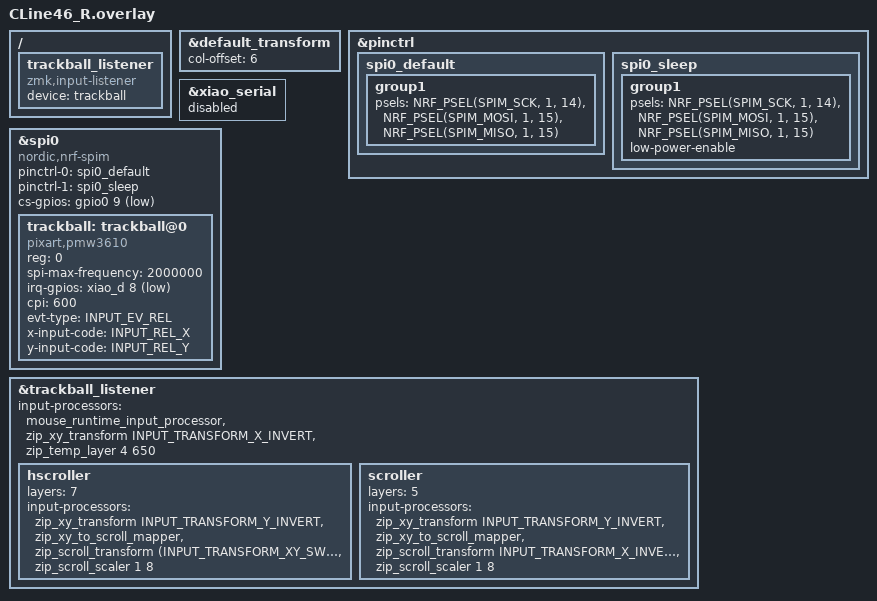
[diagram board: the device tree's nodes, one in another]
#include "CLine46.dtsi"
#include <zephyr/dt-bindings/input/input-event-codes.h>
#include <input/processors.dtsi>
#include <input/processors/runtime-input-processor.dtsi>
#include <behaviors/battery_history_request.dtsi>

&default_transform {
    col-offset = <6>;
};


/ {
    trackball_listener {
        status = "okay";
        compatible = "zmk,input-listener";
        device = <&trackball>;
    };
};

&pinctrl {
    spi0_default: spi0_default {
        group1 {
            psels = <NRF_PSEL(SPIM_SCK, 1, 14)>,
                <NRF_PSEL(SPIM_MOSI, 1, 15)>,
                <NRF_PSEL(SPIM_MISO, 1, 15)>;
        };
    };

    spi0_sleep: spi0_sleep {
        group1 {
            psels = <NRF_PSEL(SPIM_SCK, 1, 14)>,
                <NRF_PSEL(SPIM_MOSI, 1, 15)>,
                <NRF_PSEL(SPIM_MISO, 1, 15)>;
            low-power-enable;
        };
    };
};


&xiao_serial { status = "disabled"; };

&spi0 {
    status = "okay";
    compatible = "nordic,nrf-spim";
    pinctrl-0 = <&spi0_default>;
    pinctrl-1 = <&spi0_sleep>;
    pinctrl-names = "default", "sleep";
    cs-gpios = <&gpio0 9 GPIO_ACTIVE_LOW>;  //P0.09を指定(CS)

    trackball: trackball@0 {
        status = "okay";
        compatible = "pixart,pmw3610";
        reg = <0>;
        spi-max-frequency = <2000000>;
        irq-gpios = <&xiao_d 8 (GPIO_ACTIVE_LOW | GPIO_PULL_UP)>;
        cpi = <600>;
        //swap-xy;
        evt-type = <INPUT_EV_REL>;
        x-input-code = <INPUT_REL_X>;
        y-input-code = <INPUT_REL_Y>;
    };
};

// Overrides for the input listener node
&trackball_listener {
    status = "okay";
    input-processors =<&mouse_runtime_input_processor>,
        //<&zip_xy_transform INPUT_TRANSFORM_Y_INVERT>,         //Y軸反転
        //<&zip_xy_transform INPUT_TRANSFORM_XY_SWAP>,        //X軸とY軸の入れ替え
        <&zip_xy_transform INPUT_TRANSFORM_X_INVERT>,       //X軸反転
        // AML(オートマウスレイヤー): ボールを動かすと layer4(MOUSE) を 650ms 有効化。
        // keyball(QMK)既定 AUTO_MOUSE_TIME=650ms に合わせた(amlto==0 時の値, MAXは1000)。
        // west.yml で runtime-input-processor を v4移行前(1引数)SHA に固定済みのためビルド可。
        <&zip_temp_layer 4 650>;


    // ★子ノード(layer override)は「DTS の記述順に走査し、最初にマッチした1つだけ適用して
    //   打ち切り」(zmk input_listener.c: process_next 未指定なら return 0)。よって
    //   横スクロール面(7)を縦(5)より前に置くこと。薬指(&mo 5)＋小指(&mo 7)の同時ホールドで
    //   7 が優先され、小指を離すと 5 に戻る。

    // 横スクロール: layer7(HSCROLL)。keyball の「薬指＋小指ホールドで左右」と同じ操作感。
    hscroller {
        layers = <7>;
        input-processors =
            <&zip_xy_transform INPUT_TRANSFORM_Y_INVERT>,       //Y軸反転(縦と同じ前処理)
            <&zip_xy_to_scroll_mapper>,                         //スクロールモードに変更
            // XY_SWAP でホイール↔横ホイールを入替え、その後 X_INVERT が「入替え後のコード
            // (=横ホイール)」に効く(transform は swap→invert の順)。結果、ボールを下へ
            // 転がすと右へスクロール(keyball の Shift+スクロールと同じ向き)。
            <&zip_scroll_transform (INPUT_TRANSFORM_XY_SWAP | INPUT_TRANSFORM_X_INVERT)>,
            <&zip_scroll_scaler 1 8>;                           //スクロール量を1/8倍
    };

    // 縦スクロール: layer5(SCROLL)。薬指 &mo 5 を押している間。
    scroller {
        layers = <5>;
        input-processors =
            // <&zip_xy_transform INPUT_TRANSFORM_XY_SWAP>,        //X軸とY軸の入れ替え
            // <&zip_xy_transform INPUT_TRANSFORM_X_INVERT>,       //X軸反転
            <&zip_xy_transform INPUT_TRANSFORM_Y_INVERT>,       //Y軸反転
            <&zip_xy_to_scroll_mapper>,                         //スクロールモードに変更
            <&zip_scroll_transform INPUT_TRANSFORM_X_INVERT>,   //スクロールのX軸反転
            //<&zip_scroll_transform INPUT_TRANSFORM_Y_INVERT>,   //スクロールのY軸反転
            <&zip_scroll_scaler 1 8>;                           //スクロール量を1/8倍
    };
};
